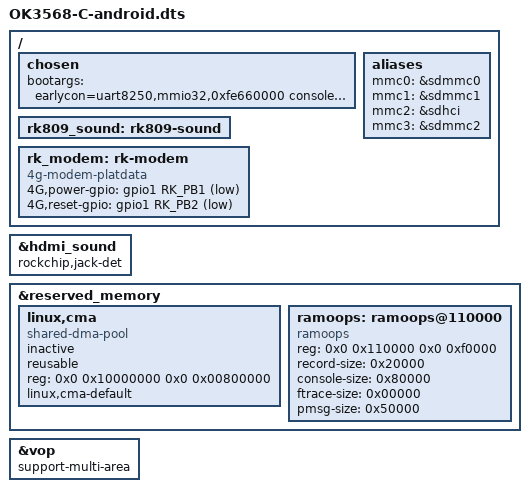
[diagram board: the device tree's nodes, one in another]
#include "OK3568-C-common.dtsi"

/ {
	chosen: chosen {
		bootargs = "earlycon=uart8250,mmio32,0xfe660000 console=ttyFIQ0";
	};

	aliases {
		mmc0 = &sdmmc0;
		mmc1 = &sdmmc1;
		mmc2 = &sdhci;
		mmc3 = &sdmmc2;
	};

	/**/
	rk809_sound: rk809-sound {
		status = "okay";
	};

	rk_modem: rk-modem {
		compatible="4g-modem-platdata";
		4G,power-gpio = <&gpio1 RK_PB1 GPIO_ACTIVE_LOW>;
		4G,reset-gpio = <&gpio1 RK_PB2 GPIO_ACTIVE_LOW>;
		status = "okay";
        };
};

/**/
&hdmi_sound {
	status = "okay";
	rockchip,jack-det;
};

&reserved_memory {
        linux,cma {
                compatible = "shared-dma-pool";
                inactive;
                reusable;
                reg = <0x0 0x10000000 0x0 0x00800000>;
                linux,cma-default;
        };

        ramoops: ramoops@110000 {
                compatible = "ramoops";
                reg = <0x0 0x110000 0x0 0xf0000>;
                record-size = <0x20000>;
                console-size = <0x80000>;
                ftrace-size = <0x00000>;
                pmsg-size = <0x50000>;
        };
};

&vop {
	support-multi-area;
};
